# CC2753 register map
File version: 1.0
CPU: CM0+ r0p4, little endian, no MPU, no FPU, VTOR, 3 interrupt priority bits
Registers are 32-bit, read-write, reset 0x0 unless marked. A register's access mark holds for its fields unless they carry their own. Offsets are from the block's base; [hi:lo] are bit positions; {n}, {i} and the like mark numbered series; 'fields as' and 'values as' point back to an identical list.

## EVTSVT — This is top module of Event Fabric for LOKI
Base 0x40025000
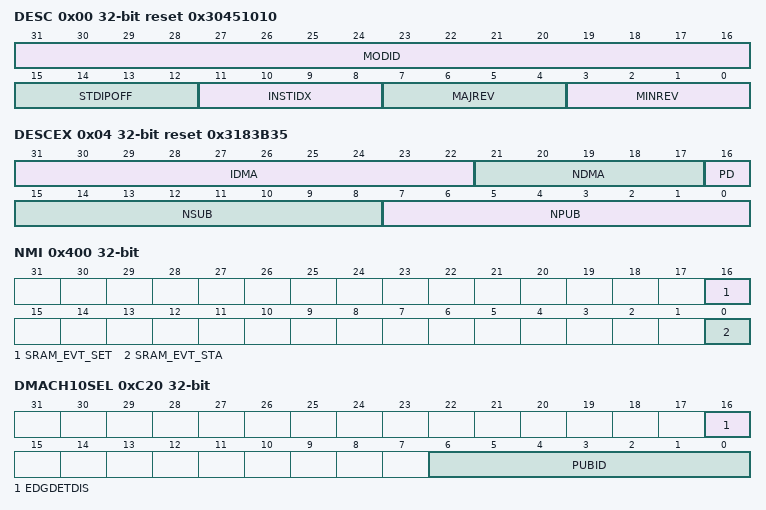
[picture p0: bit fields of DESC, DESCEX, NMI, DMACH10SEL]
0x00 DESC ro reset 0x30451010 — This register identifies the peripheral
  [31:16] MODID — Module identifier
  [15:12] STDIPOFF — 64 B Standard IP MMR block 0: STDIP MMRs do not exist 1:15: These MMRs begin at offset 64*STDIPOFF from IP base address
  [11:8] INSTIDX — IP Instance number
  [7:4] MAJREV — Major revision
  [3:0] MINREV — Minor revision
0x04 DESCEX ro reset 0x3183B35 — This register identifies the configuration of the peripheral
  [31:22] IDMA — Nember of DMA input channels
  [21:17] NDMA — Number of DMA output channels
  [16] PD — Power Domain. 0 : SVT 1 : ULL
  [15:8] NSUB — Number of Subscribers
  [7:0] NPUB — Number of Publishers
0x64 DTB — This bit field is used to select DTB mux digital inputs
  [1:0] SEL — DTB Selection
0x400 NMI — CPU NMI Interrupt Register
  [16] SRAM_EVT_SET wo — Writing a value of 1'b1 sets the corresponding NMI status flag
  [0] SRAM_EVT_STA — Read value indicates the current state of NMI flops. Writing a value of 1'b1 clears the NMI status when set.
{0x404+4i} CPUIRQ{i}SEL (i=0..4) — Output Selection for CPU Interrupt CPUIRQ{i}
  [6:0] PUBID — Read/write selection value. Writing any other value than values defined by a ENUM may result in undefined behavior.
    71=I2C1_IRQ (Interrupt event from I2C1, interrupt flags can be found here I2C1:MIS); 67=SPI1_COMB (SPI1 combined interrupt request, interrupt flags can be found here SPI1:MIS); 66=I2S_IRQ (I2S interrupt event, controlled by I2S:IRQMASK); 65=LGPT3_ADC (LGPT3 ADC trigger event, controlled by LGPT3:ADCTRG setting); 64=LGPT3_DMA (LGPT3 DMA request event, controlled by LGPT3:DMA setting); 63=LGPT3_COMB (LGPT3 combined interrupt, interrupt flags are found here LGPT3:MIS); 62=LGPT3C2 (LGPT3 compare/capture output event 2, controlled by LGPT3:C2CFG setting); 61=LGPT3C1 (LGPT3 compare/capture output event 1, controlled by LGPT3:C1CFG setting); 60=LGPT3C0 (LGPT3 compare/capture output event 0, controlled by LGPT3:C0CFG setting); 59=LGPT2_ADC (LGPT2 ADC trigger event, controlled by LGPT2:ADCTRG setting); 58=LGPT2_DMA (LGPT2 DMA request event, controlled by LGPT2:DMA setting); 57=LGPT2_COMB (LGPT2 combined interrupt, interrupt flags are found here LGPT2:MIS); 56=LGPT2C2 (LGPT0 compare/capture output event 2, controlled by LGPT2:C2CFG setting); 55=LGPT2C1 (LGPT2 compare/capture output event 1, controlled by LGPT2:C1CFG setting); 54=LGPT2C0 (LGPT2 compare/capture output event 0, controlled by LGPT2:C0CFG setting); 53=UART1_COMB (UART1 combined interrupt, interrupt flags are found here UART0:MIS); 52=LRFD_EVT2 (LRFD interrupt to SYSTIM, controlled by LRFDDBELL:SYSTIMOEV.SRC2); 51=LRFD_EVT1 (LRFD interrupt to SYSTIM, controlled by LRFDDBELL:SYSTIMOEV.SRC1); 50=LRFD_EVT0 (LRFD interrupt to SYSTIM, controlled by LRFDDBELL:SYSTIMOEV.SRC0); 49=LGPT1_ADC (LGPT1 ADC trigger event, controlled by LGPT1:ADCTRG setting); 48=LGPT1_DMA (LGPT1 DMA request event, controlled by LGPT1:DMA setting); 47=LGPT1C2 (LGPT1 compare/capture output event 2, controlled by LGPT1:C2CFG setting); 46=LGPT1C1 (LGPT1 compare/capture output event 1, controlled by LGPT1:C1CFG setting); 45=LGPT1C0 (LGPT1 compare/capture output event 0, controlled by LGPT1:C0CFG setting); 44=LGPT0_ADC (LGPT0 ADC trigger event, controlled by LGPT0:ADCTRG setting); 43=LGPT0_DMA (LGPT0 DMA request event, controlled by LGPT0:DMA setting); 42=LGPT0C2 (LGPT0 compare/capture output event 2, controlled by LGPT0:C2CFG setting); 41=LGPT0C1 (LGPT0 compare/capture output event 1, controlled by LGPT0:C1CFG setting); 40=LGPT0C0 (LGPT0 compare/capture output event 0, controlled by LGPT0:C0CFG setting); 39=SYSTIM4 (SYSTIM Channel 4 event, event flag is SYSTIM:MIS.EVT4); 38=SYSTIM3 (SYSTIM Channel 3 event, event flag is SYSTIM:MIS.EVT3); 37=SYSTIM2 (SYSTIM Channel 2 event, event flag is SYSTIM:MIS.EVT2); 36=SYSTIM1 (SYSTIM Channel 1 event, event flag isSYSTIM:MIS.EVT1); 35=SYSTIM0 (SYSTIM Channel 0 event, event flag is SYSTIM:MIS.EVT0); 34=SYSTIM_LT (SYSTIM interrupt driven by synchroinizing LFTICK signal to SVT clock); 33=SYSTIM_HB (SYSTIM heartbeat, can be set by SYSTIM:TIMEBIT); 32=I2C0_IRQ (Interrupt event from I2C0, interrupt flags can be found here I2C0:MIS); 31=UART0_COMB (UART0 combined interrupt, interrupt flags are found here UART0:MIS); 30=AES_COMB (AES accelerator combined interrupt request, interrupt flags can be found here AES:MIS); 29=DMA_ERR (DMA bus error, corresponds to DMA:ERROR.STATUS); 28=DMA_DONE_COMB (DMA combined done interrupt, corresponding flags can be found here DMA:REQDONE); 27=LGPT1_COMB (LGPT1 combined interrupt, interrupt flags are found here LGPT1:MIS); 26=LGPT0_COMB (LGPT0 combined interrupt, interrupt flags are found here LGPT0:MIS); 25=ADC_EVT (ADC general published event, interrupt flags can be found here ADC:MIS1); 24=ADC_COMB (ADC combined interrupt request, interrupt flags can be found here ADC:MIS0); 23=SPI0_COMB (SPI0 combined interrupt request, interrupt flags can be found here SPI0:MIS); 22=LRFD_IRQ2 (LRFD combined event, interrupt flags can be found here LRFDDBELL:MIS2); 21=LRFD_IRQ1 (LRFD combined event, interrupt flags can be found here LRFDDBELL:MIS1); 20=LRFD_IRQ0 (LRFD combined event, interrupt flags can be found here LRFDDBELL:MIS0); 19=FLASH_IRQ (NoWrapper Flash interrupt indicating that the flash operation has completed, interrupt flags can be found here FLASH:MIS); 18=GPIO_EVT0 (GPIO generic published event 0, controlled by GPIO:EVTCFG); 17=GPIO_COMB (GPIO combined wake up interrupt, interrupt flags can be found here GPIO:MIS); 16=SYSTIM_COMB (SYSTIM combined interrupt, interrupt flags are found here SYSTIM:MIS); 9=WURX_TIMER_EVT (WuRX timer event); 8=WURX_WAKE_EVT (WuRx wake event); 7=AON_IOC_COMB (IOC synchronous combined event, controlled by IOC:EVTCFG); 6=AON_LPCMP_IRQ (AON LPCMP interrupt, controlled by SYS0:LPCMPCFG); 5=AON_DBG_COMB (DebugSS combined interrupt, interrupt flags can be found here DBGSS:MIS); 4=AON_RTC_COMB (AON_RTC event, controlled by the RTC:IMASK setting); 3=AON_CKM_COMB (CKMD combined interrupt request, interrupt flags can be found here CKMD:MIS); 2=AON_PMU_COMB (PMU combined interrupt request for BATMON, interrupt flags can be found here PMUD:EVENT); 0=NONE (Always inactive)
0x418 CPUIRQ5SEL ro reset 0x11 — Output Selection for CPU Interrupt CPUIRQ5
  [6:0] PUBID — Read only selection value
    17=GPIO_COMB (GPIO combined wake up interrupt, interrupt flags can be found here GPIO:MIS)
0x41C CPUIRQ6SEL ro reset 0x14 — Output Selection for CPU Interrupt CPUIRQ6
  [6:0] PUBID — Read only selection value
    20=LRFD_IRQ0 (LRFD combined event, interrupt flags can be found here LRFDDBELL:MIS0)
0x420 CPUIRQ7SEL ro reset 0x15 — Output Selection for CPU Interrupt CPUIRQ7
  [6:0] PUBID — Read only selection value
    21=LRFD_IRQ1 (LRFD combined event, interrupt flags can be found here LRFDDBELL:MIS1)
0x424 CPUIRQ8SEL ro reset 0x1C — Output Selection for CPU Interrupt CPUIRQ8
  [6:0] PUBID — Read only selection value
    28=DMA_DONE_COMB (DMA combined done interrupt, corresponding flags can be found here DMA:REQDONE)
0x428 CPUIRQ9SEL ro reset 0x1E — Output Selection for CPU Interrupt CPUIRQ9
  [6:0] PUBID — Read only selection value
    30=AES_COMB (AES accelerator combined interrupt request, interrupt flags can be found here AES:MIS)
0x42C CPUIRQ10SEL ro reset 0x17 — Output Selection for CPU Interrupt CPUIRQ10
  [6:0] PUBID — Read only selection value
    23=SPI0_COMB (SPI0 combined interrupt request, interrupt flags can be found here SPI0:MIS)
0x430 CPUIRQ11SEL ro reset 0x1F — Output Selection for CPU Interrupt CPUIRQ11
  [6:0] PUBID — Read only selection value
    31=UART0_COMB (UART0 combined interrupt, interrupt flags are found here UART0:MIS)
0x434 CPUIRQ12SEL ro reset 0x20 — Output Selection for CPU Interrupt CPUIRQ12
  [6:0] PUBID — Read only selection value
    32=I2C0_IRQ (Interrupt event from I2C0, interrupt flags can be found here I2C0:MIS)
0x438 CPUIRQ13SEL ro reset 0x1A — Output Selection for CPU Interrupt CPUIRQ13
  [6:0] PUBID — Read only selection value
    26=LGPT0_COMB (LGPT0 combined interrupt, interrupt flags are found here LGPT0:MIS)
0x43C CPUIRQ14SEL ro reset 0x1B — Output Selection for CPU Interrupt CPUIRQ14
  [6:0] PUBID — Read only selection value
    27=LGPT1_COMB (LGPT1 combined interrupt, interrupt flags are found here LGPT1:MIS)
0x440 CPUIRQ15SEL ro reset 0x18 — Output Selection for CPU Interrupt CPUIRQ15
  [6:0] PUBID — Read only selection value
    24=ADC_COMB (ADC combined interrupt request, interrupt flags can be found here ADC:MIS0)
0x444 CPUIRQ16SEL — Output Selection for CPU Interrupt CPUIRQ16
  fields as CPUIRQ0SEL
0x448 CPUIRQ17SEL — Output Selection for CPU Interrupt CPUIRQ17
  fields as CPUIRQ0SEL
0x44C CPUIRQ18SEL ro reset 0x39 — Output Selection for CPU Interrupt CPUIRQ18
  [6:0] PUBID — Read only selection value
    57=LGPT2_COMB (LGPT2 combined interrupt, interrupt flags are found here LGPT2:MIS)
0x450 CPUIRQ19SEL ro reset 0x3F — Output Selection for CPU Interrupt CPUIRQ19
  [6:0] PUBID — Read only selection value
    63=LGPT3_COMB (LGPT3 combined interrupt, interrupt flags are found here LGPT3:MIS)
0x454 CPUIRQ20SEL ro reset 0x42 — Output Selection for CPU Interrupt CPUIRQ20
  [6:0] PUBID — Read only selection value
    66=I2S_IRQ (I2S interrupt event, controlled by I2S:IRQMASK)
0x458 CPUIRQ21SEL ro reset 0x47 — Output Selection for CPU Interrupt CPUIRQ21
  [6:0] PUBID — Read only selection value
    71=I2C1_IRQ (Interrupt event from I2C1, interrupt flags can be found here I2C1:MIS)
0x45C CPUIRQ22SEL ro reset 0x35 — Output Selection for CPU Interrupt CPUIRQ22
  [6:0] PUBID — Read only selection value
    53=UART1_COMB (UART1 combined interrupt, interrupt flags are found here UART0:MIS)
0x460 CPUIRQ23SEL ro reset 0x43 — Output Selection for CPU Interrupt CPUIRQ23
  [6:0] PUBID — Read only selection value
    67=SPI1_COMB (SPI1 combined interrupt request, interrupt flags can be found here SPI1:MIS)
0x464 CPUIRQ24SEL ro reset 0x44 — Output Selection for CPU Interrupt CPUIRQ24
  [6:0] PUBID — Read only selection value
    68=HSM_SEC_IRQ (HSM Secure IRQ)
0x468 CPUIRQ25SEL ro reset 0x45 — Output Selection for CPU Interrupt CPUIRQ25
  [6:0] PUBID — Read only selection value
    69=HSM_OTP_IRQ
0x46C CPUIRQ26SEL ro reset 0x2 — Output Selection for CPU Interrupt CPUIRQ26
  [6:0] PUBID — Read only selection value
    2=AON_PMU_COMB (PMU combined interrupt request for BATMON, interrupt flags can be found here PMUD:EVENT)
0x470 CPUIRQ27SEL ro reset 0x3 — Output Selection for CPU Interrupt CPUIRQ27
  [6:0] PUBID — Read only selection value
    3=AON_CKM_COMB (CKMD combined interrupt request, interrupt flags can be found here CKMD:MIS)
0x474 CPUIRQ28SEL ro reset 0x4 — Output Selection for CPU Interrupt CPUIRQ28
  [6:0] PUBID — Read only selection value
    4=AON_RTC_COMB (AON_RTC event, controlled by the RTC:IMASK setting)
0x478 CPUIRQ29SEL ro reset 0x6 — Output Selection for CPU Interrupt CPUIRQ29
  [6:0] PUBID — Read only selection value
    6=AON_LPCMP_IRQ (AON LPCMP interrupt, controlled by SYS0:LPCMPCFG)
0x47C CPUIRQ30SEL ro reset 0x7 — Output Selection for CPU Interrupt CPUIRQ30
  [6:0] PUBID — Read only selection value
    7=AON_IOC_COMB (IOC synchronous combined event, controlled by IOC:EVTCFG)
0x480 SYSTIMC0SEL — Output Selection for CPU Interrupt SYSTIMC0
  fields as CPUIRQ0SEL
0x484 SYSTIMC1SEL — Output Selection for CPU Interrupt SYSTIMC1
  fields as CPUIRQ0SEL
0x488 SYSTIMC2SEL ro reset 0x32 — Output Selection for CPU Interrupt SYSTIMC2
  [6:0] PUBID — Read only selection value
    50=LRFD_EVT0 (LRFD interrupt to SYSTIM, controlled by LRFDDBELL:SYSTIMOEV.SRC0)
0x48C SYSTIMC3SEL ro reset 0x33 — Output Selection for CPU Interrupt SYSTIMC3
  [6:0] PUBID — Read only selection value
    51=LRFD_EVT1 (LRFD interrupt to SYSTIM, controlled by LRFDDBELL:SYSTIMOEV.SRC1)
0x490 SYSTIMC4SEL ro reset 0x34 — Output Selection for CPU Interrupt SYSTIMC4
  [6:0] PUBID — Read only selection value
    52=LRFD_EVT2 (LRFD interrupt to SYSTIM, controlled by LRFDDBELL:SYSTIMOEV.SRC2)
0x494 ADCTRGSEL — Output Selection for CPU Interrupt ADCTRG
  fields as CPUIRQ0SEL
0x498 LGPTSYNCSEL — Output Selection for CPU Interrupt LGPTSYNC
  fields as CPUIRQ0SEL
{0x49C+0x10*i} LGPT{i}IN0SEL (i=0..3) — Output Selection for CPU Interrupt LGPT{i}IN0
  fields as CPUIRQ0SEL
{0x4A0+0x10*i} LGPT{i}IN1SEL (i=0..3) — Output Selection for CPU Interrupt LGPT{i}IN1
  [6:0] PUBID — Read/write selection value. Writing any other value than values defined by a ENUM may result in undefined behavior.
    65=LGPT3_ADC (LGPT3 ADC trigger event, controlled by LGPT3:ADCTRG setting); 64=LGPT3_DMA (LGPT3 DMA request event, controlled by LGPT3:DMA setting); 62=LGPT3C2 (LGPT3 compare/capture output event 2, controlled by LGPT3:C2CFG setting); 61=LGPT3C1 (LGPT3 compare/capture output event 1, controlled by LGPT3:C1CFG setting); 60=LGPT3C0 (LGPT3 compare/capture output event 0, controlled by LGPT3:C0CFG setting); 59=LGPT2_ADC (LGPT2 ADC trigger event, controlled by LGPT2:ADCTRG setting); 58=LGPT2_DMA (LGPT2 DMA request event, controlled by LGPT2:DMA setting); 56=LGPT2C2 (LGPT0 compare/capture output event 2, controlled by LGPT2:C2CFG setting); 55=LGPT2C1 (LGPT2 compare/capture output event 1, controlled by LGPT2:C1CFG setting); 54=LGPT2C0 (LGPT2 compare/capture output event 0, controlled by LGPT2:C0CFG setting); 52=LRFD_EVT2 (LRFD interrupt to SYSTIM, controlled by LRFDDBELL:SYSTIMOEV.SRC2); 51=LRFD_EVT1 (LRFD interrupt to SYSTIM, controlled by LRFDDBELL:SYSTIMOEV.SRC1); 50=LRFD_EVT0 (LRFD interrupt to SYSTIM, controlled by LRFDDBELL:SYSTIMOEV.SRC0); 49=LGPT1_ADC (LGPT1 ADC trigger event, controlled by LGPT1:ADCTRG setting); 48=LGPT1_DMA (LGPT1 DMA request event, controlled by LGPT1:DMA setting); 47=LGPT1C2 (LGPT1 compare/capture output event 2, controlled by LGPT1:C2CFG setting); 46=LGPT1C1 (LGPT1 compare/capture output event 1, controlled by LGPT1:C1CFG setting); 45=LGPT1C0 (LGPT1 compare/capture output event 0, controlled by LGPT1:C0CFG setting); 44=LGPT0_ADC (LGPT0 ADC trigger event, controlled by LGPT0:ADCTRG setting); 43=LGPT0_DMA (LGPT0 DMA request event, controlled by LGPT0:DMA setting); 42=LGPT0C2 (LGPT0 compare/capture output event 2, controlled by LGPT0:C2CFG setting); 41=LGPT0C1 (LGPT0 compare/capture output event 1, controlled by LGPT0:C1CFG setting); 40=LGPT0C0 (LGPT0 compare/capture output event 0, controlled by LGPT0:C0CFG setting); 39=SYSTIM4 (SYSTIM Channel 4 event, event flag is SYSTIM:MIS.EVT4); 38=SYSTIM3 (SYSTIM Channel 3 event, event flag is SYSTIM:MIS.EVT3); 37=SYSTIM2 (SYSTIM Channel 2 event, event flag is SYSTIM:MIS.EVT2); 36=SYSTIM1 (SYSTIM Channel 1 event, event flag isSYSTIM:MIS.EVT1); 35=SYSTIM0 (SYSTIM Channel 0 event, event flag is SYSTIM:MIS.EVT0); 34=SYSTIM_LT (SYSTIM interrupt driven by synchroinizing LFTICK signal to SVT clock); 33=SYSTIM_HB (SYSTIM heartbeat, can be set by SYSTIM:TIMEBIT); 25=ADC_EVT (ADC general published event, interrupt flags can be found here ADC:MIS1); 18=GPIO_EVT0 (GPIO generic published event 0, controlled by GPIO:EVTCFG); 9=WURX_TIMER_EVT (WuRX timer event); 8=WURX_WAKE_EVT (WuRx wake event); 0=NONE (Always inactive)
{0x4A4+0x10*i} LGPT{i}IN2SEL (i=0..3) — Output Selection for CPU Interrupt LGPT{i}IN2
  fields as LGPT0IN1SEL
{0x4A8+0x10*i} LGPT{i}TENSEL (i=0..3) — Output Selection for CPU Interrupt LGPT{i}TEN
  fields as LGPT0IN1SEL
0x4DC LRFDIN0SEL ro reset 0x25 — Output Selection for CPU Interrupt LRFDIN0
  [6:0] PUBID — Read only selection value
    37=SYSTIM2 (SYSTIM Channel 2 event, event flag is SYSTIM:MIS.EVT2)
0x4E0 LRFDIN1SEL ro reset 0x26 — Output Selection for CPU Interrupt LRFDIN1
  [6:0] PUBID — Read only selection value
    38=SYSTIM3 (SYSTIM Channel 3 event, event flag is SYSTIM:MIS.EVT3)
0x4E4 LRFDIN2SEL ro reset 0x27 — Output Selection for CPU Interrupt LRFDIN2
  [6:0] PUBID — Read only selection value
    39=SYSTIM4 (SYSTIM Channel 4 event, event flag is SYSTIM:MIS.EVT4)
0x4E8 I2SSTMPSEL — Output Selection for CPU Interrupt I2SSTMP
  fields as CPUIRQ0SEL
0xC00 DMACH0SEL — Output Selection for DMA CH0
  [3:0] IPID — Read/write selection value. Writing any other value than values defined by a ENUM may result in undefined behavior.
    11=UART1RXTRG (Selects uart1rxtrg as channel source); 0=SPI0TXTRG (Selects spi0txtrg as channel source)
0xC04 DMACH1SEL — Output Selection for DMA CH1
  [3:0] IPID — Read/write selection value. Writing any other value than values defined by a ENUM may result in undefined behavior.
    10=UART1TXTRG (Selects uart1txtrg as channel source); 1=SPI0RXTRG (Selects spi0rxtrg as channel source)
0xC08 DMACH2SEL — Output Selection for DMA CH2
  [3:0] IPID — Read/write selection value. Writing any other value than values defined by a ENUM may result in undefined behavior.
    6=UART0TXTRG (Selects uart0txtrg as channel source); 2=LRFDTRG (Selects lrfdtrg as channel source)
0xC0C DMACH3SEL — Output Selection for DMA CH3
  [3:0] IPID — Read/write selection value. Writing any other value than values defined by a ENUM may result in undefined behavior.
    7=UART0RXTRG (Selects uart0rxtrg as channel source); 5=ADC0TRG (Selects adc0trg as channel source)
0xC10 DMACH4SEL — Output Selection for DMA CH4
  [3:0] IPID — Read/write selection value. Writing any other value than values defined by a ENUM may result in undefined behavior.
    3=LAESTRGA (Selects laestrga as channel source); 2=LRFDTRG (Selects lrfdtrg as channel source)
0xC14 DMACH5SEL — Output Selection for DMA CH5
  [3:0] IPID — Read/write selection value. Writing any other value than values defined by a ENUM may result in undefined behavior.
    5=ADC0TRG (Selects adc0trg as channel source); 4=LAESTRGB (Selects laestrgb as channel source)
0xC18 DMACH6SEL ro reset 0x8 — Output Selection for DMA CH6
  [3:0] IPID — Read only selection value
    8=SPI1TXTRG (Selects spi1txtrg as channel source)
0xC1C DMACH7SEL ro reset 0x9 — Output Selection for DMA CH7
  [3:0] IPID — Read only selection value
    9=SPI1RXTRG (Selects spi1rxtrg as channel source)
0xC20 DMACH10SEL — Output Selection for DMA CH10
  [16] EDGDETDIS — Edge detect disable. 0: Enabled. 1: Disabled
  [6:0] PUBID — Read/write selection value. Writing any other value than values defined by a ENUM may result in undefined behavior.
    values as CPUIRQ0SEL.PUBID
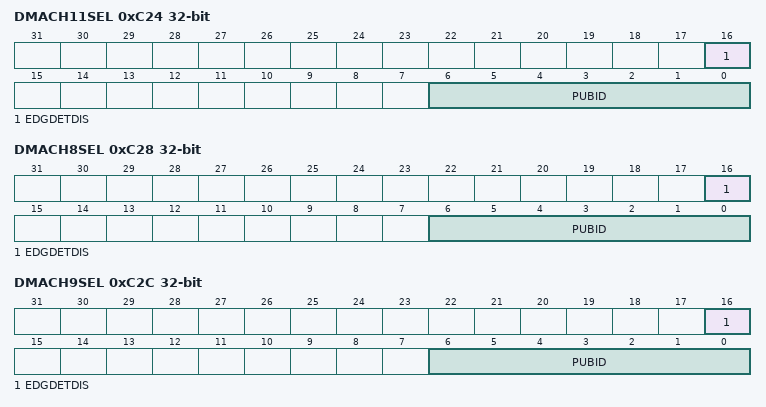
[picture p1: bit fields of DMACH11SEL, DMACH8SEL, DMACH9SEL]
0xC24 DMACH11SEL — Output Selection for DMA CH11
  fields as DMACH10SEL
0xC28 DMACH8SEL — Output Selection for DMA CH8
  fields as DMACH10SEL
0xC2C DMACH9SEL — Output Selection for DMA CH9
  fields as DMACH10SEL
